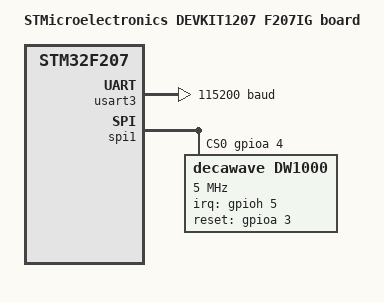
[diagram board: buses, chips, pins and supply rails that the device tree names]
/*
 * Copyright (c) 2018 hackin Zhao
 *
 * SPDX-License-Identifier: Apache-2.0
 */

/dts-v1/;
#include <st/stm32f207.dtsi>

/ {
	model = "STMicroelectronics DEVKIT1207 F207IG board";
	compatible = "st,stm32f207ig-devkit1207", "st,stm32f207";

	chosen {
		zephyr,console = &usart3;
		zephyr,sram = &sram0;
		zephyr,flash = &flash0;
	};
};

&usart3 {
	current-speed = <115200>;
	pinctrl-2 = <&usart3_pins_c>;
	pinctrl-names = "default";
	status = "ok";
};

&spi1 {
	cs-gpios = <&gpioa 4 0>;
	status = "ok";

	dw1000@0 {
		compatible = "decawave,dw1000";
		reg = <0x0>;
		label = "dw1000";
		spi-max-frequency = <5000000>;
		irq-gpios = <&gpioh 5 0>;
		reset-gpios = <&gpioa 3 0>;
		status = "ok";
	};
};
